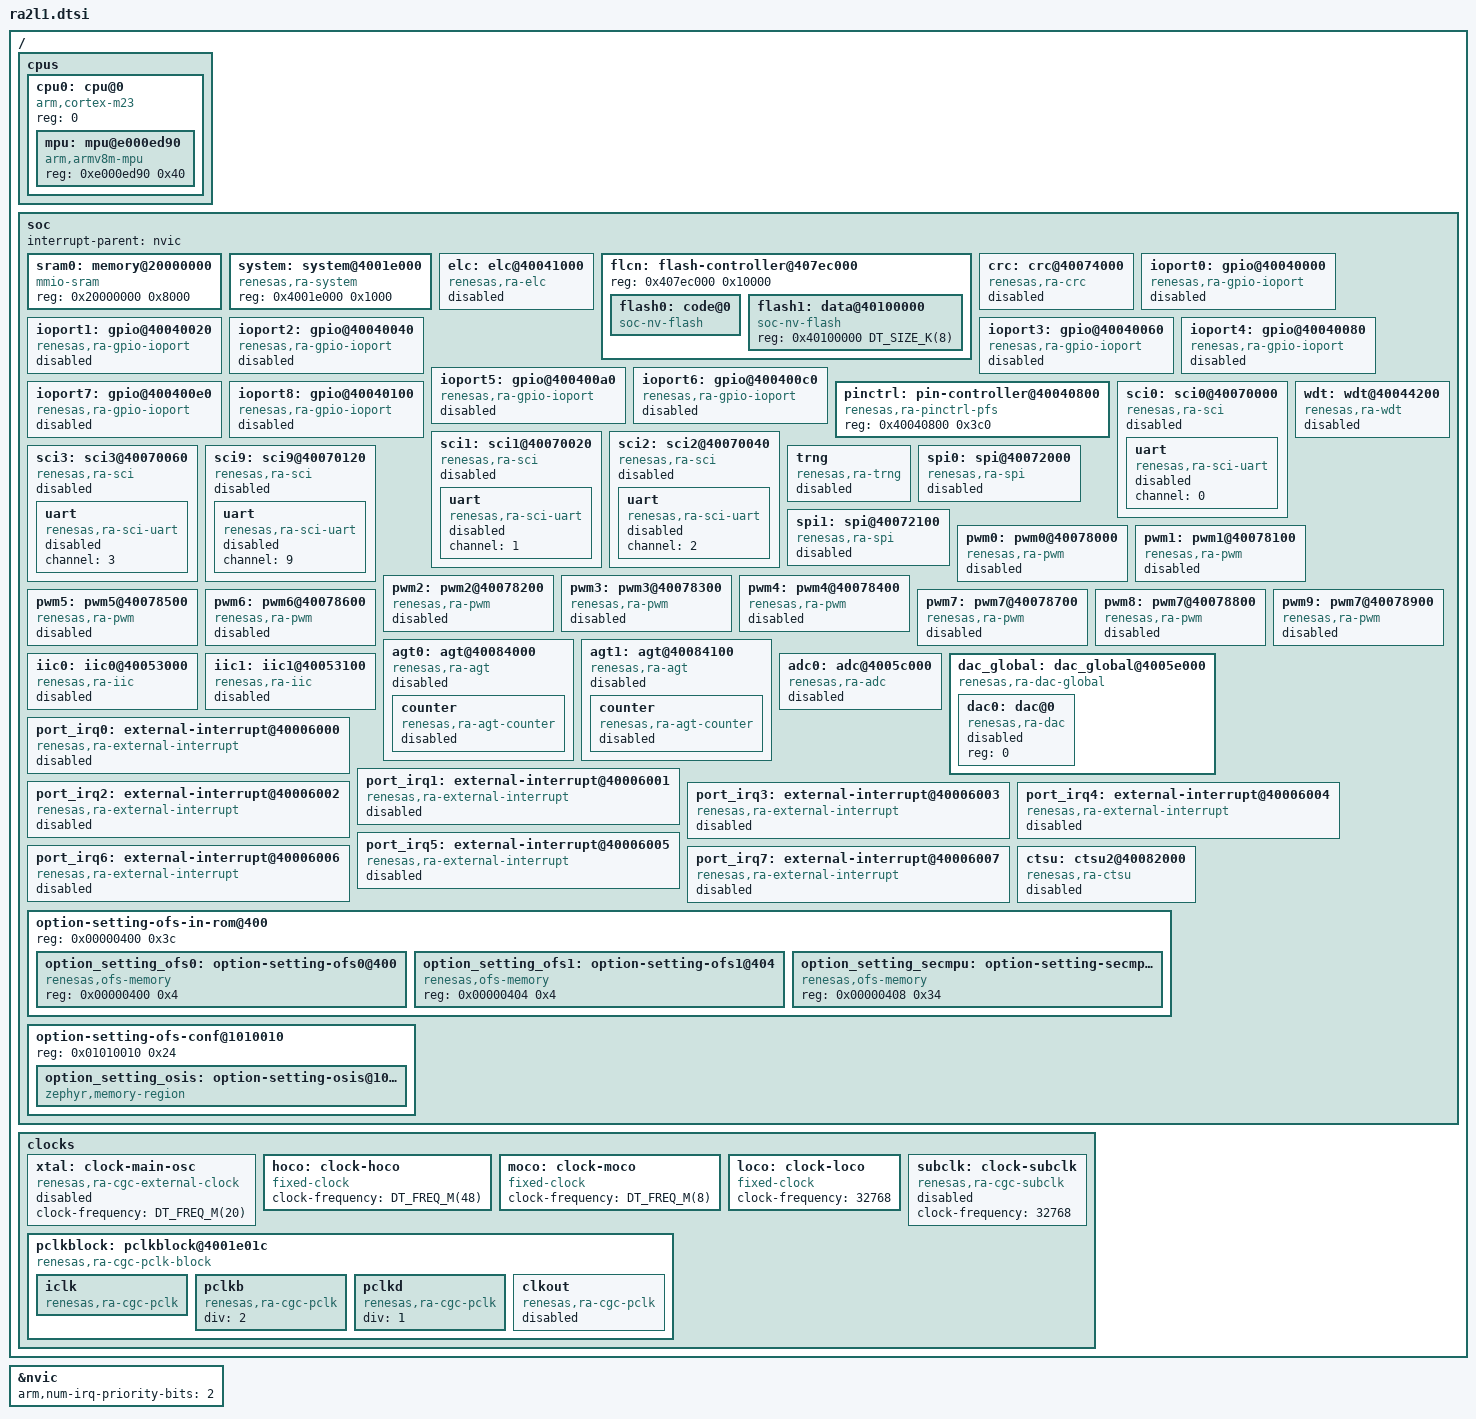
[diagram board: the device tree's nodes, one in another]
/**
 * Copyright (c) 2021-2024 MUNIC SA
 * Copyright (c) 2024-2025 Renesas Electronics Corporation
 *
 * Renesas RA2L1 MCU series device tree
 *
 * SPDX-License-Identifier: Apache-2.0
 */

#include <freq.h>
#include <mem.h>
#include <arm/armv8-m.dtsi>
#include <zephyr/dt-bindings/pinctrl/renesas/pinctrl-ra.h>
#include <zephyr/dt-bindings/clock/ra_clock.h>
#include <zephyr/dt-bindings/misc/renesas/ra-elc/ra2l1-elc.h>
#include <zephyr/dt-bindings/pwm/ra_pwm.h>

/ {
	cpus {
		#address-cells = <1>;
		#size-cells = <0>;

		cpu0: cpu@0 {
			device_type = "cpu";
			compatible = "arm,cortex-m23";
			reg = <0>;
			#address-cells = <1>;
			#size-cells = <1>;

			mpu: mpu@e000ed90 {
				compatible = "arm,armv8m-mpu";
				reg = <0xe000ed90 0x40>;
			};
		};
	};

	soc {
		interrupt-parent = <&nvic>;

		sram0: memory@20000000 {
			compatible = "mmio-sram";
			reg = <0x20000000 0x8000>;
		};

		system: system@4001e000 {
			compatible = "renesas,ra-system";
			reg = <0x4001e000 0x1000>;
			status = "okay";
		};

		elc: elc@40041000 {
			compatible = "renesas,ra-elc";
			reg = <0x40041000 0x6c>;
			#renesas-elc-cells = <2>;
			clocks = <&pclkb MSTPC 14>;
			status = "disabled";
		};

		flcn: flash-controller@407ec000 {
			reg = <0x407ec000 0x10000>;

			#address-cells = <1>;
			#size-cells = <1>;

			flash0: code@0 {
				compatible = "soc-nv-flash";
				/* "reg" property should be defined in the
				 * chip specific .dtsi file
				 */
			};

			flash1: data@40100000 {
				compatible = "soc-nv-flash";
				reg = <0x40100000 DT_SIZE_K(8)>;
			};
		};

		crc: crc@40074000 {
			compatible = "renesas,ra-crc";
			reg = <0x40074000 0x1000>;
			clocks = <&pclkb MSTPC 1>;
			status = "disabled";
		};

		ioport0: gpio@40040000 {
			compatible = "renesas,ra-gpio-ioport";
			reg = <0x40040000 0x20>;
			port = <0>;
			gpio-controller;
			#gpio-cells = <2>;
			ngpios = <16>;
			status = "disabled";
		};

		ioport1: gpio@40040020 {
			compatible = "renesas,ra-gpio-ioport";
			reg = <0x40040020 0x20>;
			port = <1>;
			gpio-controller;
			#gpio-cells = <2>;
			ngpios = <16>;
			status = "disabled";
		};

		ioport2: gpio@40040040 {
			compatible = "renesas,ra-gpio-ioport";
			reg = <0x40040040 0x20>;
			port = <2>;
			gpio-controller;
			#gpio-cells = <2>;
			ngpios = <16>;
			status = "disabled";
		};

		ioport3: gpio@40040060 {
			compatible = "renesas,ra-gpio-ioport";
			reg = <0x40040060 0x20>;
			port = <3>;
			gpio-controller;
			#gpio-cells = <2>;
			ngpios = <16>;
			status = "disabled";
		};

		ioport4: gpio@40040080 {
			compatible = "renesas,ra-gpio-ioport";
			reg = <0x40040080 0x20>;
			port = <4>;
			gpio-controller;
			#gpio-cells = <2>;
			ngpios = <16>;
			status = "disabled";
		};

		ioport5: gpio@400400a0 {
			compatible = "renesas,ra-gpio-ioport";
			reg = <0x400400a0 0x20>;
			port = <5>;
			gpio-controller;
			#gpio-cells = <2>;
			ngpios = <16>;
			status = "disabled";
		};

		ioport6: gpio@400400c0 {
			compatible = "renesas,ra-gpio-ioport";
			reg = <0x400400c0 0x20>;
			port = <6>;
			gpio-controller;
			#gpio-cells = <2>;
			ngpios = <16>;
			status = "disabled";
		};

		ioport7: gpio@400400e0 {
			compatible = "renesas,ra-gpio-ioport";
			reg = <0x400400e0 0x20>;
			port = <7>;
			gpio-controller;
			#gpio-cells = <2>;
			ngpios = <16>;
			status = "disabled";
		};

		ioport8: gpio@40040100 {
			compatible = "renesas,ra-gpio-ioport";
			reg = <0x40040100 0x20>;
			port = <8>;
			gpio-controller;
			#gpio-cells = <2>;
			ngpios = <16>;
			status = "disabled";
		};

		pinctrl: pin-controller@40040800 {
			compatible = "renesas,ra-pinctrl-pfs";
			reg = <0x40040800 0x3c0>;
			status = "okay";
		};

		sci0: sci0@40070000 {
			compatible = "renesas,ra-sci";
			interrupts = <0 1>, <1 1>, <2 1>, <3 1>;
			interrupt-names = "rxi", "txi", "tei", "eri";
			reg = <0x40070000 0x100>;
			clocks = <&pclkb MSTPB 31>;
			status = "disabled";

			uart {
				compatible = "renesas,ra-sci-uart";
				channel = <0>;
				status = "disabled";
			};
		};

		sci1: sci1@40070020 {
			compatible = "renesas,ra-sci";
			reg = <0x40070020 0x100>;
			clocks = <&pclkb MSTPB 30>;
			status = "disabled";

			uart {
				compatible = "renesas,ra-sci-uart";
				channel = <1>;
				status = "disabled";
			};
		};

		sci2: sci2@40070040 {
			compatible = "renesas,ra-sci";
			reg = <0x40070040 0x100>;
			clocks = <&pclkb MSTPB 29>;
			status = "disabled";

			uart {
				compatible = "renesas,ra-sci-uart";
				channel = <2>;
				status = "disabled";
			};
		};

		sci3: sci3@40070060 {
			compatible = "renesas,ra-sci";
			reg = <0x40070060 0x100>;
			clocks = <&pclkb MSTPB 28>;
			status = "disabled";

			uart {
				compatible = "renesas,ra-sci-uart";
				channel = <3>;
				status = "disabled";
			};
		};

		sci9: sci9@40070120 {
			compatible = "renesas,ra-sci";
			interrupts = <4 1>, <5 1>, <6 1>, <7 1>;
			interrupt-names = "rxi", "txi", "tei", "eri";
			reg = <0x40070120 0x100>;
			clocks = <&pclkb MSTPB 22>;
			status = "disabled";

			uart {
				compatible = "renesas,ra-sci-uart";
				channel = <9>;
				status = "disabled";
			};
		};

		wdt: wdt@40044200 {
			compatible = "renesas,ra-wdt";
			reg = <0x40044200 0x200>;
			clocks = <&pclkb 0 0>;
			status = "disabled";
		};

		trng: trng {
			compatible = "renesas,ra-trng";
			status = "disabled";
		};

		spi0: spi@40072000 {
			compatible = "renesas,ra-spi";
			#address-cells = <1>;
			#size-cells = <0>;
			channel = <0>;
			reg = <0x40072000 0x100>;
			status = "disabled";
		};

		spi1: spi@40072100 {
			compatible = "renesas,ra-spi";
			#address-cells = <1>;
			#size-cells = <0>;
			channel = <1>;
			reg = <0x40072100 0x100>;
			status = "disabled";
		};

		pwm0: pwm0@40078000 {
			compatible = "renesas,ra-pwm";
			divider = <RA_PWM_SOURCE_DIV_1>;
			channel = <RA_PWM_CHANNEL_0>;
			clocks = <&pclkd MSTPD 5>;
			reg = <0x40078000 0x100>;
			#pwm-cells = <3>;
			status = "disabled";
		};

		pwm1: pwm1@40078100 {
			compatible = "renesas,ra-pwm";
			divider = <RA_PWM_SOURCE_DIV_1>;
			channel = <RA_PWM_CHANNEL_1>;
			clocks = <&pclkd MSTPD 5>;
			reg = <0x40078100 0x100>;
			#pwm-cells = <3>;
			status = "disabled";
		};

		pwm2: pwm2@40078200 {
			compatible = "renesas,ra-pwm";
			divider = <RA_PWM_SOURCE_DIV_1>;
			channel = <RA_PWM_CHANNEL_2>;
			clocks = <&pclkd MSTPD 5>;
			reg = <0x40078200 0x100>;
			#pwm-cells = <3>;
			status = "disabled";
		};

		pwm3: pwm3@40078300 {
			compatible = "renesas,ra-pwm";
			divider = <RA_PWM_SOURCE_DIV_1>;
			channel = <RA_PWM_CHANNEL_3>;
			clocks = <&pclkd MSTPD 5>;
			reg = <0x40078300 0x100>;
			#pwm-cells = <3>;
			status = "disabled";
		};

		pwm4: pwm4@40078400 {
			compatible = "renesas,ra-pwm";
			divider = <RA_PWM_SOURCE_DIV_1>;
			channel = <RA_PWM_CHANNEL_4>;
			clocks = <&pclkd MSTPD 6>;
			reg = <0x40078400 0x100>;
			#pwm-cells = <3>;
			status = "disabled";
		};

		pwm5: pwm5@40078500 {
			compatible = "renesas,ra-pwm";
			divider = <RA_PWM_SOURCE_DIV_1>;
			channel = <RA_PWM_CHANNEL_5>;
			clocks = <&pclkd MSTPD 6>;
			reg = <0x40078500 0x100>;
			#pwm-cells = <3>;
			status = "disabled";
		};

		pwm6: pwm6@40078600 {
			compatible = "renesas,ra-pwm";
			divider = <RA_PWM_SOURCE_DIV_1>;
			channel = <RA_PWM_CHANNEL_6>;
			clocks = <&pclkd MSTPD 6>;
			reg = <0x40078600 0x100>;
			#pwm-cells = <3>;
			status = "disabled";
		};

		pwm7: pwm7@40078700 {
			compatible = "renesas,ra-pwm";
			divider = <RA_PWM_SOURCE_DIV_1>;
			channel = <RA_PWM_CHANNEL_7>;
			clocks = <&pclkd MSTPD 6>;
			reg = <0x40078700 0x100>;
			#pwm-cells = <3>;
			status = "disabled";
		};

		pwm8: pwm7@40078800 {
			compatible = "renesas,ra-pwm";
			divider = <RA_PWM_SOURCE_DIV_1>;
			channel = <RA_PWM_CHANNEL_8>;
			clocks = <&pclkd MSTPD 6>;
			reg = <0x40078800 0x100>;
			#pwm-cells = <3>;
			status = "disabled";
		};

		pwm9: pwm7@40078900 {
			compatible = "renesas,ra-pwm";
			divider = <RA_PWM_SOURCE_DIV_1>;
			channel = <RA_PWM_CHANNEL_9>;
			clocks = <&pclkd MSTPD 6>;
			reg = <0x40078900 0x100>;
			#pwm-cells = <3>;
			status = "disabled";
		};

		agt0: agt@40084000 {
			compatible = "renesas,ra-agt";
			channel = <0>;
			reg = <0x40084000 0x100>;
			renesas,count-source = "AGT_CLOCK_LOCO";
			renesas,prescaler = <0>;
			renesas,resolution = <16>;
			status = "disabled";

			counter {
				compatible = "renesas,ra-agt-counter";
				status = "disabled";
			};
		};

		agt1: agt@40084100 {
			compatible = "renesas,ra-agt";
			channel = <1>;
			reg = <0x40084100 0x100>;
			renesas,count-source = "AGT_CLOCK_LOCO";
			renesas,prescaler = <0>;
			renesas,resolution = <16>;
			status = "disabled";

			counter {
				compatible = "renesas,ra-agt-counter";
				status = "disabled";
			};
		};

		iic0: iic0@40053000 {
			compatible = "renesas,ra-iic";
			channel = <0>;
			reg = <0x40053000 0x100>;
			status = "disabled";
		};

		iic1: iic1@40053100 {
			compatible = "renesas,ra-iic";
			channel = <1>;
			reg = <0x40053100 0x100>;
			status = "disabled";
		};

		adc0: adc@4005c000 {
			compatible = "renesas,ra-adc";
			reg = <0x4005c000 0x100>;
			#io-channel-cells = <1>;
			vref-mv = <3300>;
			channel-available-mask = <0x1e7fff>;
			status = "disabled";
		};

		dac_global: dac_global@4005e000 {
			compatible = "renesas,ra-dac-global";
			reg = <0x4005e000 0x10c4>;
			#address-cells = <1>;
			#size-cells = <0>;

			dac0: dac@0 {
				compatible = "renesas,ra-dac";
				#io-channel-cells = <1>;
				reg = <0>;
				status = "disabled";
			};
		};

		port_irq0: external-interrupt@40006000 {
			compatible = "renesas,ra-external-interrupt";
			reg = <0x40006000 0x1>;
			channel = <0>;
			renesas,sample-clock-div = <64>;
			#port-irq-cells = <0>;
			status = "disabled";
		};

		port_irq1: external-interrupt@40006001 {
			compatible = "renesas,ra-external-interrupt";
			reg = <0x40006001 0x1>;
			channel = <1>;
			renesas,sample-clock-div = <64>;
			#port-irq-cells = <0>;
			status = "disabled";
		};

		port_irq2: external-interrupt@40006002 {
			compatible = "renesas,ra-external-interrupt";
			reg = <0x40006002 0x1>;
			channel = <2>;
			renesas,sample-clock-div = <64>;
			#port-irq-cells = <0>;
			status = "disabled";
		};

		port_irq3: external-interrupt@40006003 {
			compatible = "renesas,ra-external-interrupt";
			reg = <0x40006003 0x1>;
			channel = <3>;
			renesas,sample-clock-div = <64>;
			#port-irq-cells = <0>;
			status = "disabled";
		};

		port_irq4: external-interrupt@40006004 {
			compatible = "renesas,ra-external-interrupt";
			reg = <0x40006004 0x1>;
			channel = <4>;
			renesas,sample-clock-div = <64>;
			#port-irq-cells = <0>;
			status = "disabled";
		};

		port_irq5: external-interrupt@40006005 {
			compatible = "renesas,ra-external-interrupt";
			reg = <0x40006005 0x1>;
			channel = <5>;
			renesas,sample-clock-div = <64>;
			#port-irq-cells = <0>;
			status = "disabled";
		};

		port_irq6: external-interrupt@40006006 {
			compatible = "renesas,ra-external-interrupt";
			reg = <0x40006006 0x1>;
			channel = <6>;
			renesas,sample-clock-div = <64>;
			#port-irq-cells = <0>;
			status = "disabled";
		};

		port_irq7: external-interrupt@40006007 {
			compatible = "renesas,ra-external-interrupt";
			reg = <0x40006007 0x1>;
			channel = <7>;
			renesas,sample-clock-div = <64>;
			#port-irq-cells = <0>;
			status = "disabled";
		};

		ctsu: ctsu2@40082000 {
			compatible = "renesas,ra-ctsu";
			reg = <0x40082000 0x70>;
			clocks = <&pclkb MSTPC 3>;
			variant = "ctsu2";
			status = "disabled";
		};

		option-setting-ofs-in-rom@400 {
			reg = <0x00000400 0x3c>;
			#address-cells = <1>;
			#size-cells = <1>;

			option_setting_ofs0: option-setting-ofs0@400 {
				compatible = "renesas,ofs-memory";
				reg = <0x00000400 0x4>;
				status = "okay";
			};

			option_setting_ofs1: option-setting-ofs1@404 {
				compatible = "renesas,ofs-memory";
				reg = <0x00000404 0x4>;
				status = "okay";
			};

			option_setting_secmpu: option-setting-secmpu@408 {
				compatible = "renesas,ofs-memory";
				reg = <0x00000408 0x34>;
				status = "okay";
			};
		};

		option-setting-ofs-conf@1010010 {
			reg = <0x01010010 0x24>;
			#address-cells = <1>;
			#size-cells = <1>;
			status = "okay";

			option_setting_osis: option-setting-osis@1010018 {
				compatible = "zephyr,memory-region";
				zephyr,memory-region = "OFS_OSIS_MEMORY";
				reg = <0x01010018 0x1c>;
				status = "okay";
			};
		};
	};

	clocks: clocks {
		#address-cells = <1>;
		#size-cells = <1>;

		xtal: clock-main-osc {
			compatible = "renesas,ra-cgc-external-clock";
			clock-frequency = <DT_FREQ_M(20)>;
			#clock-cells = <0>;
			status = "disabled";
		};

		hoco: clock-hoco {
			compatible = "fixed-clock";
			clock-frequency = <DT_FREQ_M(48)>;
			#clock-cells = <0>;
		};

		moco: clock-moco {
			compatible = "fixed-clock";
			clock-frequency = <DT_FREQ_M(8)>;
			#clock-cells = <0>;
		};

		loco: clock-loco {
			compatible = "fixed-clock";
			clock-frequency = <32768>;
			#clock-cells = <0>;
		};

		subclk: clock-subclk {
			compatible = "renesas,ra-cgc-subclk";
			clock-frequency = <32768>;
			#clock-cells = <0>;
			status = "disabled";
		};

		pclkblock: pclkblock@4001e01c {
			compatible = "renesas,ra-cgc-pclk-block";
			reg = <0x4001e01c 4>, <0x40047000 4>, <0x40047004 4>,
			      <0x40047008 4>;
			reg-names = "MSTPA", "MSTPB", "MSTPC",
				    "MSTPD";
			#clock-cells = <0>;
			clocks = <&hoco>;
			status = "okay";

			iclk: iclk {
				compatible = "renesas,ra-cgc-pclk";
				clock-frequency = <48000000>;
				div = <1>;
				#clock-cells = <2>;
				status = "okay";
			};

			pclkb: pclkb {
				compatible = "renesas,ra-cgc-pclk";
				div = <2>;
				#clock-cells = <2>;
				status = "okay";
			};

			pclkd: pclkd {
				compatible = "renesas,ra-cgc-pclk";
				div = <1>;
				#clock-cells = <2>;
				status = "okay";
			};

			clkout: clkout {
				compatible = "renesas,ra-cgc-pclk";
				#clock-cells = <2>;
				status = "disabled";
			};
		};
	};
};

&nvic {
	arm,num-irq-priority-bits = <2>;
};

&dac_global {
	has-davrefcr;
};
